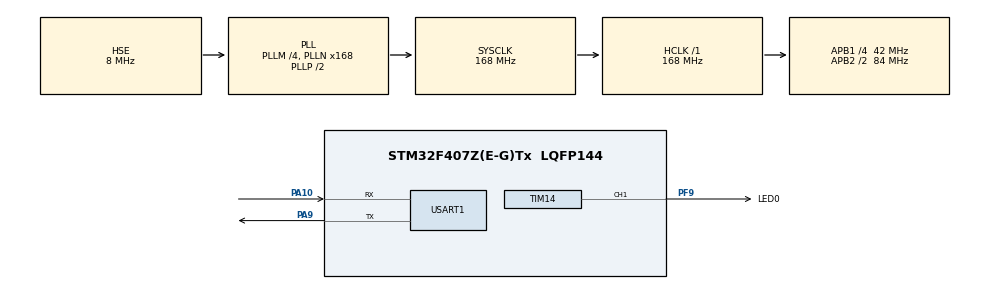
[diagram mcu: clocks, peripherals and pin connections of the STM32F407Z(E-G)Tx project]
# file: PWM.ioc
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Mcu.Family=STM32F4
Mcu.Name=STM32F407Z(E-G)Tx
Mcu.Package=LQFP144
NVIC.PriorityGroup=NVIC_PRIORITYGROUP_4
PA10.Mode=Asynchronous
PA10.Signal=USART1_RX
PA13.Mode=Serial_Wire
PA13.Signal=SYS_JTMS-SWDIO
PA14.Mode=Serial_Wire
PA14.Signal=SYS_JTCK-SWCLK
PA9.Mode=Asynchronous
PA9.Signal=USART1_TX
PF9.GPIO_Label=LED0
PF9.Signal=S_TIM14_CH1
PH0-OSC_IN.Mode=HSE-External-Oscillator
PH0-OSC_IN.Signal=RCC_OSC_IN
PH1-OSC_OUT.Mode=HSE-External-Oscillator
PH1-OSC_OUT.Signal=RCC_OSC_OUT
ProjectManager.HeapSize=0x200
ProjectManager.StackSize=0x400
ProjectManager.TargetToolchain=SW4STM32
RCC.48MHZClocksFreq_Value=84000000
RCC.AHBFreq_Value=168000000
RCC.APB1CLKDivider=RCC_HCLK_DIV4
RCC.APB1Freq_Value=42000000
RCC.APB1TimFreq_Value=84000000
RCC.APB2CLKDivider=RCC_HCLK_DIV2
RCC.APB2Freq_Value=84000000
RCC.APB2TimFreq_Value=168000000
RCC.CortexFreq_Value=168000000
RCC.HCLKFreq_Value=168000000
RCC.HSE_VALUE=8000000
RCC.HSI_VALUE=16000000
RCC.LSE_VALUE=32768
RCC.PLLM=4
RCC.PLLN=168
RCC.PLLSourceVirtual=RCC_PLLSOURCE_HSE
RCC.SYSCLKFreq_VALUE=168000000
RCC.SYSCLKSource=RCC_SYSCLKSOURCE_PLLCLK
RCC.VCOOutputFreq_Value=336000000
SH.S_TIM14_CH1.0=TIM14_CH1,PWM Generation1 CH1
TIM14.Channel=TIM_CHANNEL_1
TIM14.OCPolarity_1=TIM_OCPOLARITY_LOW
TIM14.Period=499
TIM14.Prescaler=83
USART1.VirtualMode=VM_ASYNC
VP_TIM14_VS_ClockSourceINT.Mode=Enable_Timer
board=custom

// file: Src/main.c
/* USER CODE BEGIN Header */
/**
  ******************************************************************************
  * @file           : main.c
  * @brief          : Main program body
  ******************************************************************************
  * @attention
  *
  * <h2><center>&copy; Copyright (c) 2020 STMicroelectronics.
  * All rights reserved.</center></h2>
  *
  * This software component is licensed by ST under BSD 3-Clause license,
  * the "License"; You may not use this file except in compliance with the
  * License. You may obtain a copy of the License at:
  *                        opensource.org/licenses/BSD-3-Clause
  *
  ******************************************************************************
  */
/* USER CODE END Header */

#include "main.h"
#include "tim.h"
#include "usart.h"
#include "gpio.h"

/* USER CODE BEGIN Includes */
#include <stdio.h>
#include "retarget.h"
/* USER CODE END Includes */

void SystemClock_Config(void);

int main(void)
{
  /* USER CODE BEGIN 1 */
    uint8_t dir=1;
    uint16_t led0pwmval=0;
  /* USER CODE END 1 */

  /* MCU Configuration--------------------------------------------------------*/

  /* Reset of all peripherals, Initializes the Flash interface and the Systick. */
  HAL_Init();

  /* Configure the system clock */
  SystemClock_Config();

  /* Initialize all configured peripherals */
  MX_GPIO_Init();
  MX_USART1_UART_Init();
  MX_TIM14_Init();
  /* USER CODE BEGIN 2 */
    RetargetInit(&huart1);
    HAL_TIM_PWM_Start(&htim14,TIM_CHANNEL_1);//使能输出
  /* USER CODE END 2 */

  /* Infinite loop */
  while (1)
  {

    /* USER CODE BEGIN 3 */
      if(dir)led0pwmval++;				//dir==1 led0pwmval递增
      else led0pwmval--;					//dir==0 led0pwmval递减
      if(led0pwmval>300)dir=0;			//led0pwmval到达300后，方向为递减
      if(led0pwmval==0)dir=1;				//led0pwmval递减到0后，方向改为递增
      __HAL_TIM_SetCompare(&htim14, TIM_CHANNEL_1, led0pwmval);    //修改比较值，修改占空比
      HAL_Delay(10);
  }
  /* USER CODE END 3 */
}

void SystemClock_Config(void)
{
  RCC_OscInitTypeDef RCC_OscInitStruct = {0};
  RCC_ClkInitTypeDef RCC_ClkInitStruct = {0};

  /** Configure the main internal regulator output voltage
  */
  __HAL_RCC_PWR_CLK_ENABLE();
  __HAL_PWR_VOLTAGESCALING_CONFIG(PWR_REGULATOR_VOLTAGE_SCALE1);
  /** Initializes the CPU, AHB and APB busses clocks
  */
  RCC_OscInitStruct.OscillatorType = RCC_OSCILLATORTYPE_HSE;
  RCC_OscInitStruct.HSEState = RCC_HSE_ON;
  RCC_OscInitStruct.PLL.PLLState = RCC_PLL_ON;
  RCC_OscInitStruct.PLL.PLLSource = RCC_PLLSOURCE_HSE;
  RCC_OscInitStruct.PLL.PLLM = 4;
  RCC_OscInitStruct.PLL.PLLN = 168;
  RCC_OscInitStruct.PLL.PLLP = RCC_PLLP_DIV2;
  RCC_OscInitStruct.PLL.PLLQ = 4;
  if (HAL_RCC_OscConfig(&RCC_OscInitStruct) != HAL_OK)
  {
    Error_Handler();
  }
  /** Initializes the CPU, AHB and APB busses clocks
  */
  RCC_ClkInitStruct.ClockType = RCC_CLOCKTYPE_HCLK|RCC_CLOCKTYPE_SYSCLK
                              |RCC_CLOCKTYPE_PCLK1|RCC_CLOCKTYPE_PCLK2;
  RCC_ClkInitStruct.SYSCLKSource = RCC_SYSCLKSOURCE_PLLCLK;
  RCC_ClkInitStruct.AHBCLKDivider = RCC_SYSCLK_DIV1;
  RCC_ClkInitStruct.APB1CLKDivider = RCC_HCLK_DIV4;
  RCC_ClkInitStruct.APB2CLKDivider = RCC_HCLK_DIV2;

  if (HAL_RCC_ClockConfig(&RCC_ClkInitStruct, FLASH_LATENCY_5) != HAL_OK)
  {
    Error_Handler();
  }
}

void Error_Handler(void)
{
}

/************************ (C) COPYRIGHT STMicroelectronics *****END OF FILE****/
